VERSION ""

NS_ :

BS_:

BU_: CMC_UNIT

BO_ 100 HANDSHAKE: 16 CMC_UNIT
 SG_ hw_version_major : 0|8@1+ (1,0) [0|255] ""  CMC_UNIT
 SG_ hw_version_minor : 8|8@1+ (1,0) [0|255] ""  CMC_UNIT
 SG_ unit_id : 16|8@1+ (1,0) [0|255] ""  CMC_UNIT
 SG_ unit_type : 24|8@1+ (1,0) [0|255] ""  CMC_UNIT
 SG_ fw_version_major : 32|8@1+ (1,0) [0|255] ""  CMC_UNIT
 SG_ fw_version_minor : 40|8@1+ (1,0) [0|255] ""  CMC_UNIT
 SG_ gc_datetime : 48|32@1+ (1,0) [0|4294967295] ""  CMC_UNIT
 SG_ gc_hash : 80|32@1+ (1,0) [0|4294967295] ""  CMC_UNIT

BO_ 101 HEARTBEAT: 1 CMC_UNIT
 SG_ unit_id : 0|6@1+ (1,0) [0|63] ""  CMC_UNIT
 SG_ system_state : 6|2@1+ (1,0) [0|3] ""  CMC_UNIT

BO_ 202 FEATURE_HORN: 1 CMC_UNIT
 SG_ value_on_off : 0|1@1+ (1,0) [0|1] "" Vector__XXX

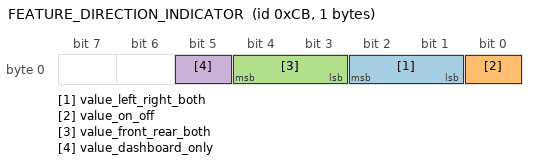
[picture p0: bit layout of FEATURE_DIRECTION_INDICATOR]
BO_ 203 FEATURE_DIRECTION_INDICATOR: 1 CMC_UNIT
 SG_ value_left_right_both : 1|2@1+ (1,0) [0|2] "" Vector__XXX
 SG_ value_on_off : 0|1@1+ (1,0) [0|1] "" Vector__XXX
 SG_ value_front_rear_both : 3|2@1+ (1,0) [0|2] "" Vector__XXX
 SG_ value_dashboard_only : 5|1@1+ (1,0) [0|1] "" Vector__XXX

BO_ 200 FEATURE_IGNITION: 8 CMC_UNIT
 SG_ value_on_off : 0|1@1+ (1,0) [0|1] "" Vector__XXX

BO_ 201 FEATURE_STARTER: 8 CMC_UNIT
 SG_ value_on_off : 0|1@1+ (1,0) [0|1] "" Vector__XXX

CM_ BO_ 100 "Startup init to check ID and FW for all units, inititate reset or reconfig if needed";
CM_ SG_ 100 hw_version_major "Hardware major version";
CM_ SG_ 100 hw_version_minor "Hardware minor version";
CM_ SG_ 100 unit_id "Unique ID for the source unit";
CM_ SG_ 100 unit_type "Unit type";
CM_ SG_ 100 fw_version_major "Firmware major version, should listed for compability to ensure units can be combined";
CM_ SG_ 100 fw_version_minor "Firmware minor version, for info only";
CM_ SG_ 100 gc_datetime "All global configs across all units must be the same, datetime is when the config was created/updated, if not the same across units or if missing, the most recent updated config is to be used and passed over to units with old config";
CM_ SG_ 100 gc_hash "All global configs across all units must be the same, this hash represent global config checksum";
CM_ BO_ 101 "Poll on system frequently to identify missing units or mishaps";
CM_ SG_ 101 unit_id "Unique ID for the source unit";
CM_ SG_ 101 system_state "Report system state for taking action if not OK";
CM_ BO_ 202 "Turn horn on/off";
CM_ SG_ 202 value_on_off "0=off, 1=on";
CM_ BO_ 203 "Turn direction indicators on/off, send also info for left, righ or both (hazard) and optionally if to be turned of only for front or rear, normally should be both. Separate for turning on indicator only, to be used for startup animation or check that dashboard indicator bulb works";
CM_ SG_ 203 value_left_right_both "0=left, 1=right, 2=both";
CM_ SG_ 203 value_on_off "0=off, 1=on";
CM_ SG_ 203 value_front_rear_both "0=front, 1=rear, 2=both";
CM_ SG_ 203 value_dashboard_only "0=normal operation, 1=only affect dashboard warning indicator";
CM_ BO_ 200 "Control ignition status";
CM_ SG_ 200 value_on_off "0=off, 1=on";
CM_ BO_ 201 "Control starter motor";
CM_ SG_ 201 value_on_off "0=off, 1=engaged (on)";
BA_DEF_  "BusType" STRING ;
BA_DEF_ BO_  "CANFD_BRS" ENUM  "0","1";
BA_DEF_ BO_  "VFrameFormat" ENUM  "StandardCAN","ExtendedCAN","reserved","reserved","reserved","reserved","reserved","reserved","reserved","reserved","reserved","reserved","reserved","reserved","StandardCAN_FD","ExtendedCAN_FD";
BA_DEF_DEF_  "BusType" "";
BA_DEF_DEF_  "CANFD_BRS" "0";
BA_DEF_DEF_  "VFrameFormat" "StandardCAN";
BA_ "BusType" "CAN FD";
BA_ "VFrameFormat" BO_ 100 14;
BA_ "CANFD_BRS" BO_ 100 1;
VAL_ 100 unit_type 0 "UNKNOWN" 1 "I/O UNIT" ;
VAL_ 101 system_state 0 "UNKNOWN" 1 "OK" 2 "WARNING" 3 "FAULT" ;
